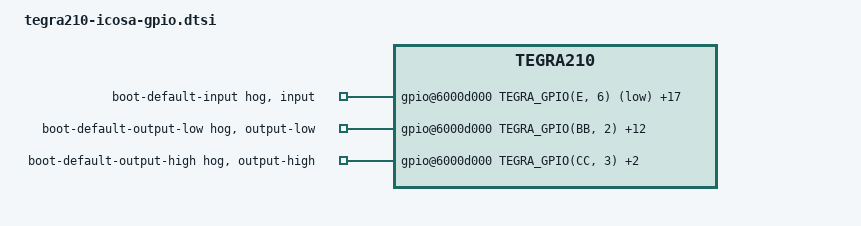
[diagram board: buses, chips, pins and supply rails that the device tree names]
/*
 * Copyright (c) 2014-2016, NVIDIA CORPORATION.  All rights reserved.
 *
 * This program is free software; you can redistribute it and/or modify
 * it under the terms of the GNU General Public License as published by
 * the Free Software Foundation; either version 2 of the License, or
 * (at your option) any later version.
 *
 * This program is distributed in the hope that it will be useful, but WITHOUT
 * ANY WARRANTY; without even the implied warranty of MERCHANTABILITY or
 * FITNESS FOR A PARTICULAR PURPOSE.  See the GNU General Public License for
 * more details.
 *
 * You should have received a copy of the GNU General Public License along
 * with this program; if not, write to the Free Software Foundation, Inc.,
 * 51 Franklin Street, Fifth Floor, Boston, MA  02110-1301, USA.
 */

#include <dt-bindings/gpio/tegra-gpio.h>

/ {
	gpio@6000d000 {
		boot-default-input {
			gpio-hog;
			input;
			gpios = <
				TEGRA_GPIO(E, 6) 1 /* Joycon (L) Wake Detect */
				TEGRA_GPIO(X, 4) 0 /* Temperature Sensor (TMP451) Alert */
				TEGRA_GPIO(X, 2) 1 /* Motion IRQ (Unused?) */
				TEGRA_GPIO(X, 1) 0 /* Touchscreen (4CD60D) IRQ */
				TEGRA_GPIO(X, 5) 0 /* Sleep Button 2 (Unused?) */
				TEGRA_GPIO(X, 6) 0 /* Volume Up Button */
				TEGRA_GPIO(X, 7) 0 /* Volume Down Button */
				TEGRA_GPIO(Y, 1) 1 /* Home Button (RCM) */
				TEGRA_GPIO(Y, 0) 0 /* Fuel Gauge IC (MAX17050) IRQ */
				TEGRA_GPIO(Z, 0) 0 /* Charger IC (BQ24193) IRQ */
				TEGRA_GPIO(S, 1) 1 /* Charger IC (BQ24193) Battery Charge Status */
				TEGRA_GPIO(K, 4) 0 /* USB-PD (BM92T36) IRQ */
				TEGRA_GPIO(H, 2) 1 /* Wi-Fi Wake Host */
				TEGRA_GPIO(H, 5) 1 /* Bluetooth - BT Module -> Wake AP */
				TEGRA_GPIO(H, 6) 1 /* Joycon (R) Wake Detect */
				TEGRA_GPIO(P, 0) 1
				TEGRA_GPIO(V, 6) 1 /* Audio Codec (ALC5639) Headphone Detect */
				TEGRA_GPIO(BB, 4) 0 /* Audio Codec (ALC5639) Alert */
				>;
			line-name = "boot-default-input";
		};

		boot-default-output-low {
			gpio-hog;
			output-low;
			gpios = <
				TEGRA_GPIO(BB, 2) 0
				TEGRA_GPIO(BB, 3) 0 /* Gamecard Reset */
				TEGRA_GPIO(S, 5) 0
				TEGRA_GPIO(T, 0) 0
				TEGRA_GPIO(T, 1) 0
				TEGRA_GPIO(V, 2) 0  /* LCD Reset */
				TEGRA_GPIO(V, 5) 0  /* USB-PD (BM92T36) Reset */
				TEGRA_GPIO(K, 5) 0  /* USB-PD (BM92T36) VCONN Power Enable */
				TEGRA_GPIO(L, 0) 0
				TEGRA_GPIO(H, 0) 0  /* Wi-Fi RF Disable */
				TEGRA_GPIO(H, 3) 0  /* Bluetooth - AP -> Wake BT Module */
				TEGRA_GPIO(H, 4) 0  /* Bluetooth Reset */
				TEGRA_GPIO(I, 2) 0
				>;
			line-name = "boot-default-output-low";
		};

		boot-default-output-high {
			gpio-hog;
			output-high;
			gpios = <
				TEGRA_GPIO(CC, 3) 0 /* Joycon (L) Charge Enable */
				TEGRA_GPIO(K, 3) 0  /* Joycon (R) Charge Enable */
				TEGRA_GPIO(H, 1) 0  /* Wi-Fi Reset. Powered on by default. */
				>;
			line-name = "boot-default-output-high";
		};

		system-suspend-output-low {
			gpio-suspend;
			suspend-output-low;
			output-low;
			gpios = <
				TEGRA_GPIO(CC, 3) 0 /* Joycon (L) Charge Enable */
				TEGRA_GPIO(K, 3) 0  /* Joycon (R) Charge Enable */
				TEGRA_GPIO(V, 0) 0  /* LCD Backlight PWM */
				TEGRA_GPIO(V, 1) 0  /* LCD Backlight Enable */
				TEGRA_GPIO(V, 2) 0  /* LCD Reset */
				>;
		};
	};
};
